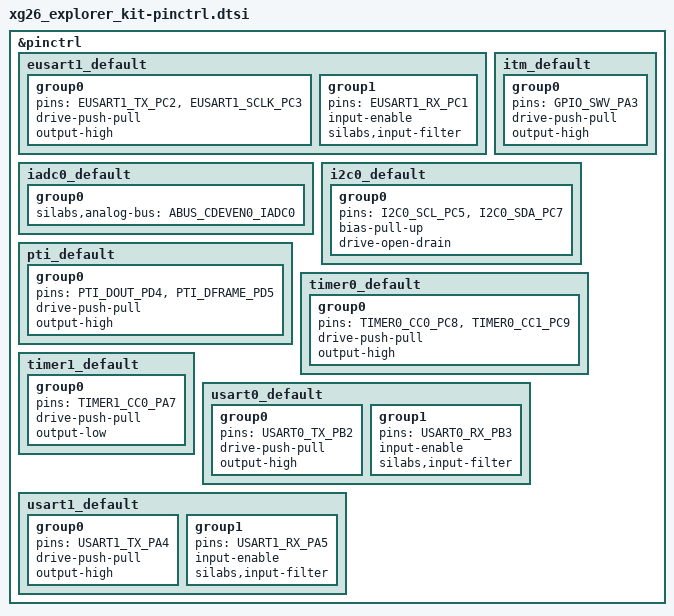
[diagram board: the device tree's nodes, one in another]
/*
 * Copyright The Zephyr Project Contributors
 *
 * SPDX-License-Identifier: Apache-2.0
 */

#include <dt-bindings/pinctrl/silabs/xg26-pinctrl.h>

&pinctrl {
	eusart1_default: eusart1_default {
		group0 {
			pins = <EUSART1_TX_PC2>, <EUSART1_SCLK_PC3>;
			drive-push-pull;
			output-high;
		};

		group1 {
			pins = <EUSART1_RX_PC1>;
			input-enable;
			silabs,input-filter;
		};
	};

	iadc0_default: iadc0_default {
		group0 {
			silabs,analog-bus = <ABUS_CDEVEN0_IADC0>;
		};
	};

	itm_default: itm_default {
		group0 {
			pins = <GPIO_SWV_PA3>;
			drive-push-pull;
			output-high;
		};
	};

	i2c0_default: i2c0_default {
		group0 {
			pins = <I2C0_SCL_PC5>, <I2C0_SDA_PC7>;
			bias-pull-up;
			drive-open-drain;
		};
	};

	pti_default: pti_default {
		group0 {
			pins = <PTI_DOUT_PD4>, <PTI_DFRAME_PD5>;
			drive-push-pull;
			output-high;
		};
	};

	timer0_default: timer0_default {
		group0 {
			pins = <TIMER0_CC0_PC8>, <TIMER0_CC1_PC9>;
			drive-push-pull;
			output-high;
		};
	};

	timer1_default: timer1_default {
		group0 {
			pins = <TIMER1_CC0_PA7>;
			drive-push-pull;
			output-low;
		};
	};

	usart0_default: usart0_default {
		group0 {
			pins = <USART0_TX_PB2>;
			drive-push-pull;
			output-high;
		};

		group1 {
			pins = <USART0_RX_PB3>;
			input-enable;
			silabs,input-filter;
		};
	};

	usart1_default: usart1_default {
		group0 {
			pins = <USART1_TX_PA4>;
			drive-push-pull;
			output-high;
		};

		group1 {
			pins = <USART1_RX_PA5>;
			input-enable;
			silabs,input-filter;
		};
	};
};
